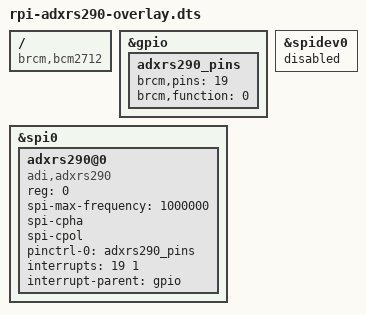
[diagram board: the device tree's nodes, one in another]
// SPDX-License-Identifier: GPL-2.0
/dts-v1/;
/plugin/;

/ {
	compatible = "brcm,bcm2712", "brcm,bcm2836", "brcm,bcm2835";

	fragment@0 {
		target = <&gpio>;
		__overlay__ {
			adxrs290_pins: adxrs290_pins {
				brcm,pins = <19>;
				brcm,function = <0>; /* GPIO input */
			};
		};
	};

	fragment@1 {
		target = <&spi0>;
		__overlay__ {
			#address-cells = <1>;
			#size-cells = <0>;
			status = "okay";

			adxrs290@0 {
				compatible = "adi,adxrs290";
				reg = <0>;
				spi-max-frequency = <1000000>;
				spi-cpha;
				spi-cpol;
				pinctrl-names = "default";
				pinctrl-0 = <&adxrs290_pins>;
				interrupts = <19 1>;
				interrupt-parent = <&gpio>;
			};
		};
	};

	fragment@2 {
		target = <&spidev0>;
		__overlay__ {
			status = "disabled";
		};
	};
};
